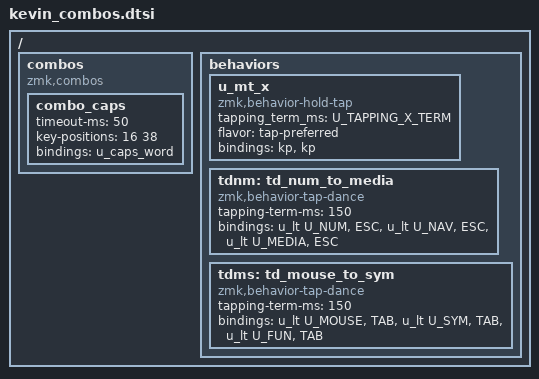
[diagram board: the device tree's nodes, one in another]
/ {
  combos {
    compatible = "zmk,combos";
    combo_caps {
        timeout-ms = <50>;
        key-positions = <16 38>;
        bindings = <&u_caps_word>;
    };
  };
  behaviors {
    u_mt_x: u_mt_x {
      compatible = "zmk,behavior-hold-tap";
      #binding-cells = <2>;
      tapping_term_ms = <U_TAPPING_X_TERM>;
      flavor = "tap-preferred";
      bindings = <&kp>, <&kp>;
    };
    tdnm: td_num_to_media {
      compatible = "zmk,behavior-tap-dance";
      #binding-cells = <0>;
      tapping-term-ms = <150>;
      bindings = <&u_lt U_NUM, ESC>, <&u_lt U_NAV, ESC>, <&u_lt U_MEDIA, ESC>;
    };
    tdms: td_mouse_to_sym {
      compatible = "zmk,behavior-tap-dance";
      #binding-cells = <0>;
      tapping-term-ms = <150>;
      bindings = <&u_lt U_MOUSE, TAB>, <&u_lt U_SYM, TAB>, <&u_lt U_FUN, TAB>;
    };
  };
};
